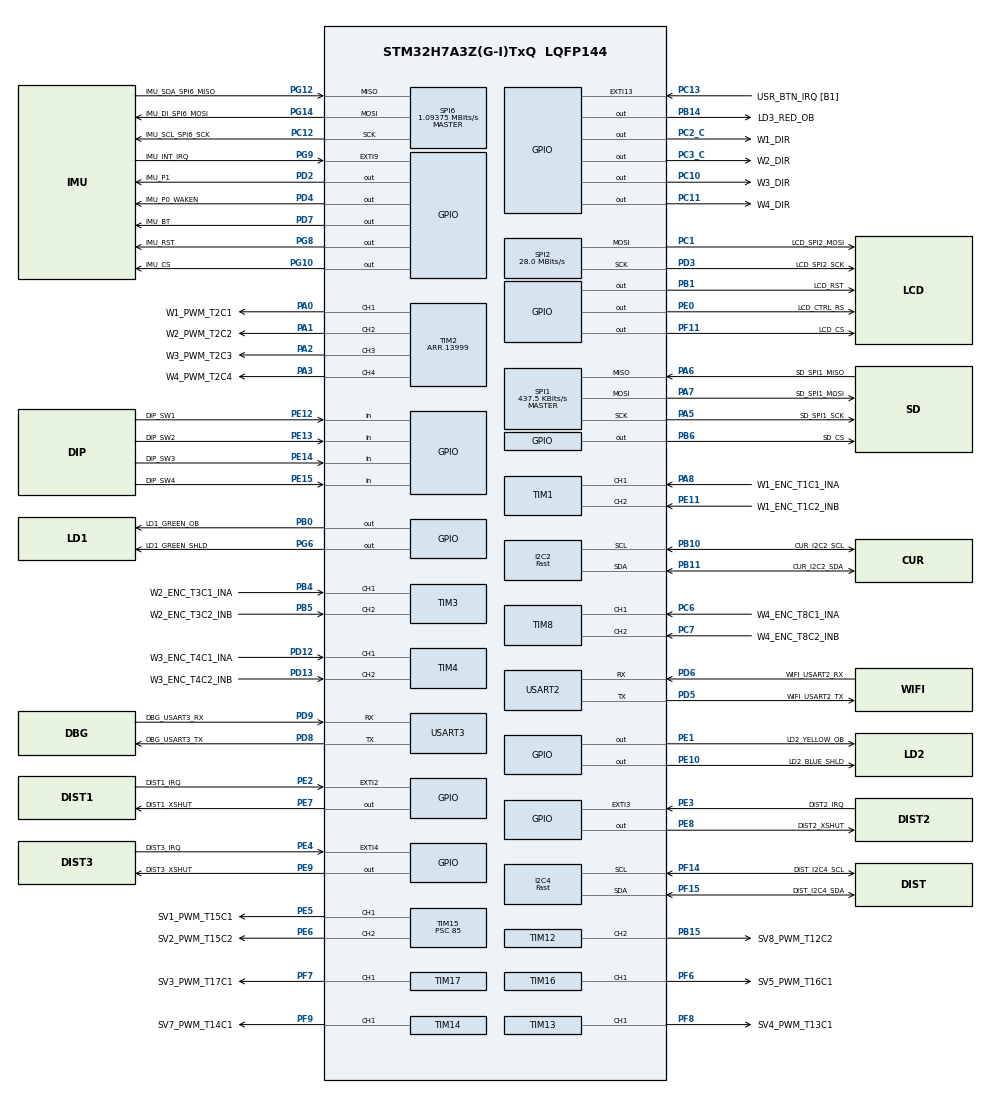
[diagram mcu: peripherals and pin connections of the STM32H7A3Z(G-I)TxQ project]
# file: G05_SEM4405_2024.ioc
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ADC2.Channel-0\#ChannelRegularConversion=ADC_CHANNEL_TEMPSENSOR
ADC2.ContinuousConvMode=ENABLE
ADC2.NbrOfConversionFlag=1
ADC2.OffsetNumber-0\#ChannelRegularConversion=ADC_OFFSET_NONE
ADC2.OffsetSignedSaturation-0\#ChannelRegularConversion=DISABLE
ADC2.Rank-0\#ChannelRegularConversion=1
ADC2.SamplingTime-0\#ChannelRegularConversion=ADC_SAMPLETIME_810CYCLES_5
FREERTOS.BinarySemaphores01=SemaUartTx,Dynamic,NULL
FREERTOS.Events01=eventSysFlags,Dynamic,NULL;eventLcdReady,Dynamic,NULL;eventUartTxReady,Dynamic,NULL;eventUartRxReady,Dynamic,NULL
FREERTOS.Tasks01=debugPrintTask,24,2048,StartDebugPrintTask,Default,&robot,Dynamic,NULL,NULL;adcTask,40,2048,StartAdcTask,Default,&robot,Dynamic,NULL,NULL;curSenTask,40,2048,StartCurSenTask,Default,&robot,Dynamic,NULL,NULL;distSenTask,40,2048,StartDistSenTask,Default,&robot,Dynamic,NULL,NULL;sdCardTask,8,2048,StartSdCardTask,Default,&robot,Dynamic,NULL,NULL;mtrEncoderTask,48,2048,StartMtrEncoderTask,Default,&robot,Dynamic,NULL,NULL;srvPwmUpdateTask,40,2048,StartSrvPwmUpdateTask,Default,&robot,Dynamic,NULL,NULL;cmdRxTask,40,2048,StartCmdRxTask,Default,&robot,Dynamic,NULL,NULL;guiLcdDispTask,24,2048,StartGuiLcdDispTask,Default,&robot,Dynamic,NULL,NULL;imuTask,40,2048,StartImuTask,Default,&robot ,Dynamic,NULL,NULL
FREERTOS.configCHECK_FOR_STACK_OVERFLOW=2
FREERTOS.configMAX_TASK_NAME_LEN=18
FREERTOS.configMINIMAL_STACK_SIZE=1024
FREERTOS.configTOTAL_HEAP_SIZE=204800
FREERTOS.configUSE_MALLOC_FAILED_HOOK=1
FREERTOS.configUSE_NEWLIB_REENTRANT=1
I2C2.I2C_Speed_Mode=I2C_Fast
I2C2.OwnAddress=0x40
I2C2.Timing=0x00D04BFF
I2C4.I2C_Speed_Mode=I2C_Fast
I2C4.OwnAddress=0x29
I2C4.Timing=0x00D04BFF
Mcu.Family=STM32H7
Mcu.Name=STM32H7A3Z(G-I)TxQ
Mcu.Package=LQFP144
NVIC.ADC_IRQn=true\:5\:0\:false\:false\:true\:true\:true\:true\:true
NVIC.EXTI15_10_IRQn=true\:5\:0\:false\:false\:true\:true\:true\:true\:true
NVIC.EXTI2_IRQn=true\:5\:0\:false\:false\:true\:true\:true\:true\:true
NVIC.EXTI3_IRQn=true\:5\:0\:false\:false\:true\:true\:true\:true\:true
NVIC.EXTI4_IRQn=true\:5\:0\:false\:false\:true\:true\:true\:true\:true
NVIC.EXTI9_5_IRQn=true\:5\:0\:false\:false\:true\:true\:true\:true\:true
NVIC.PriorityGroup=NVIC_PRIORITYGROUP_4
NVIC.SPI2_IRQn=true\:5\:0\:false\:false\:true\:true\:true\:true\:true
NVIC.SPI6_IRQn=true\:5\:0\:false\:false\:true\:true\:true\:true\:true
NVIC.TIM7_IRQn=true\:15\:0\:false\:false\:true\:false\:false\:true\:true
NVIC.TimeBase=TIM7_IRQn
NVIC.TimeBaseIP=TIM7
NVIC.USART2_IRQn=true\:5\:0\:false\:false\:true\:true\:true\:true\:true
PA0.GPIO_Label=W1_PWM_T2C1 
PA0.Signal=S_TIM2_CH1_ETR
PA1.GPIO_Label=W2_PWM_T2C2 
PA1.Signal=S_TIM2_CH2
PA13.GPIO_Label=DBG_SWDIO
PA13.Mode=Trace_Asynchronous_SW
PA13.Signal=DEBUG_JTMS-SWDIO
PA14.GPIO_Label=DBG_SWCLK
PA14.Mode=Trace_Asynchronous_SW
PA14.Signal=DEBUG_JTCK-SWCLK
PA2.GPIO_Label=W3_PWM_T2C3
PA2.Signal=S_TIM2_CH3
PA3.GPIO_Label=W4_PWM_T2C4 
PA3.Signal=S_TIM2_CH4
PA5.GPIO_Label=SD_SPI1_SCK
PA5.GPIO_Speed=GPIO_SPEED_FREQ_VERY_HIGH
PA5.Mode=Full_Duplex_Master
PA5.Signal=SPI1_SCK
PA6.GPIO_Label=SD_SPI1_MISO 
PA6.GPIO_PuPd=GPIO_PULLUP
PA6.GPIO_Speed=GPIO_SPEED_FREQ_VERY_HIGH
PA6.Mode=Full_Duplex_Master
PA6.Signal=SPI1_MISO
PA7.GPIO_Label=SD_SPI1_MOSI 
PA7.GPIO_PuPd=GPIO_PULLUP
PA7.GPIO_Speed=GPIO_SPEED_FREQ_VERY_HIGH
PA7.Mode=Full_Duplex_Master
PA7.Signal=SPI1_MOSI
PA8.GPIO_Label=W1_ENC_T1C1_INA
PA8.Signal=S_TIM1_CH1
PB0.GPIO_Label=LD1_GREEN_OB
PB0.Signal=GPIO_Output
PB1.GPIO_Label=LCD_RST
PB1.Signal=GPIO_Output
PB10.GPIO_Label=CUR_I2C2_SCL
PB10.Mode=I2C
PB10.Signal=I2C2_SCL
PB11.GPIO_Label=CUR_I2C2_SDA
PB11.Mode=I2C
PB11.Signal=I2C2_SDA
PB14.GPIO_Label=LD3_RED_OB
PB14.Signal=GPIO_Output
PB15.GPIO_Label=SV8_PWM_T12C2
PB15.Signal=S_TIM12_CH2
PB3.GPIO_Label=DBG_SWO
PB3.Mode=Trace_Asynchronous_SW
PB3.Signal=DEBUG_JTDO-SWO
PB4.GPIO_Label=W2_ENC_T3C1_INA
PB4.Signal=S_TIM3_CH1
PB5.GPIO_Label=W2_ENC_T3C2_INB
PB5.Signal=S_TIM3_CH2
PB6.GPIO_Label=SD_CS
PB6.Signal=GPIO_Output
PC1.GPIO_Label=LCD_SPI2_MOSI
PC1.GPIO_Speed=GPIO_SPEED_FREQ_VERY_HIGH
PC1.Mode=TX_Only_Simplex_Unidirect_Master
PC1.Signal=SPI2_MOSI
PC10.GPIO_Label=W3_DIR
PC10.Signal=GPIO_Output
PC11.GPIO_Label=W4_DIR
PC11.Signal=GPIO_Output
PC12.GPIO_Label=IMU_SCL_SPI6_SCK
PC12.GPIO_Speed=GPIO_SPEED_FREQ_VERY_HIGH
PC12.Mode=Full_Duplex_Master
PC12.Signal=SPI6_SCK
PC13.GPIO_Label=USR_BTN_IRQ [B1] 
PC13.Signal=GPXTI13
PC14-OSC32_IN.GPIO_Label=OSC32_IN
PC14-OSC32_IN.Mode=LSE-External-Oscillator
PC14-OSC32_IN.Signal=RCC_OSC32_IN
PC15-OSC32_OUT.GPIO_Label=OSC32_OUT
PC15-OSC32_OUT.Mode=LSE-External-Oscillator
PC15-OSC32_OUT.Signal=RCC_OSC32_OUT
PC2_C.GPIO_Label=W1_DIR
PC2_C.Signal=GPIO_Output
PC3_C.GPIO_Label=W2_DIR
PC3_C.Signal=GPIO_Output
PC6.GPIO_Label=W4_ENC_T8C1_INA
PC6.Signal=S_TIM8_CH1
PC7.GPIO_Label=W4_ENC_T8C2_INB 
PC7.Signal=S_TIM8_CH2
PD12.GPIO_Label=W3_ENC_T4C1_INA
PD12.Signal=S_TIM4_CH1
PD13.GPIO_Label=W3_ENC_T4C2_INB
PD13.Signal=S_TIM4_CH2
PD2.GPIO_Label=IMU_P1
PD2.Signal=GPIO_Output
PD3.GPIO_Label=LCD_SPI2_SCK
PD3.GPIO_Speed=GPIO_SPEED_FREQ_VERY_HIGH
PD3.Mode=TX_Only_Simplex_Unidirect_Master
PD3.Signal=SPI2_SCK
PD4.GPIO_Label=IMU_P0_WAKEN
PD4.Signal=GPIO_Output
PD5.GPIO_Label=WIFI_USART2_TX
PD5.Mode=Asynchronous
PD5.Signal=USART2_TX
PD6.GPIO_Label=WIFI_USART2_RX
PD6.Mode=Asynchronous
PD6.Signal=USART2_RX
PD7.GPIO_Label=IMU_BT
PD7.Signal=GPIO_Output
PD8.GPIO_Label=DBG_USART3_TX
PD8.Mode=Asynchronous
PD8.Signal=USART3_TX
PD9.GPIO_Label=DBG_USART3_RX
PD9.Mode=Asynchronous
PD9.Signal=USART3_RX
PE0.GPIO_Label=LCD_CTRL_RS
PE0.Signal=GPIO_Output
PE1.GPIO_Label=LD2_YELLOW_OB 
PE1.Signal=GPIO_Output
PE10.GPIO_Label=LD2_BLUE_SHLD
PE10.Signal=GPIO_Output
PE11.GPIO_Label=W1_ENC_T1C2_INB
PE11.Signal=S_TIM1_CH2
PE12.GPIO_Label=DIP_SW1
PE12.Signal=GPIO_Input
PE13.GPIO_Label=DIP_SW2
PE13.Signal=GPIO_Input
PE14.GPIO_Label=DIP_SW3
PE14.Signal=GPIO_Input
PE15.GPIO_Label=DIP_SW4 
PE15.Signal=GPIO_Input
PE2.GPIO_Label=DIST1_IRQ
PE2.Signal=GPXTI2
PE3.GPIO_Label=DIST2_IRQ
PE3.Signal=GPXTI3
PE4.GPIO_Label=DIST3_IRQ
PE4.Signal=GPXTI4
PE5.GPIO_Label=SV1_PWM_T15C1
PE5.Signal=S_TIM15_CH1
PE6.GPIO_Label=SV2_PWM_T15C2
PE6.Signal=S_TIM15_CH2
PE7.GPIO_Label=DIST1_XSHUT
PE7.Signal=GPIO_Output
PE8.GPIO_Label=DIST2_XSHUT
PE8.Signal=GPIO_Output
PE9.GPIO_Label=DIST3_XSHUT
PE9.Signal=GPIO_Output
PF11.GPIO_Label=LCD_CS
PF11.Signal=GPIO_Output
PF14.GPIO_Label=DIST_I2C4_SCL
PF14.Mode=I2C
PF14.Signal=I2C4_SCL
PF15.GPIO_Label=DIST_I2C4_SDA
PF15.Mode=I2C
PF15.Signal=I2C4_SDA
PF6.GPIO_Label=SV5_PWM_T16C1
PF6.Signal=S_TIM16_CH1
PF7.GPIO_Label=SV3_PWM_T17C1 
PF7.Signal=S_TIM17_CH1
PF8.GPIO_Label=SV4_PWM_T13C1
PF8.Signal=S_TIM13_CH1
PF9.GPIO_Label=SV7_PWM_T14C1
PF9.Signal=S_TIM14_CH1
PG10.GPIO_Label=IMU_CS
PG10.Signal=GPIO_Output
PG12.GPIO_Label=IMU_SDA_SPI6_MISO
PG12.GPIO_Speed=GPIO_SPEED_FREQ_VERY_HIGH
PG12.Mode=Full_Duplex_Master
PG12.Signal=SPI6_MISO
PG14.GPIO_Label=IMU_DI_SPI6_MOSI 
PG14.GPIO_Speed=GPIO_SPEED_FREQ_VERY_HIGH
PG14.Mode=Full_Duplex_Master
PG14.Signal=SPI6_MOSI
PG6.GPIO_Label=LD1_GREEN_SHLD
PG6.Signal=GPIO_Output
PG8.GPIO_Label=IMU_RST
PG8.Signal=GPIO_Output
PG9.GPIO_Label=IMU_INT_IRQ
PG9.GPIO_ModeDefaultEXTI=GPIO_MODE_IT_FALLING
PG9.GPIO_PuPd=GPIO_PULLUP
PG9.Signal=GPXTI9
PH0-OSC_IN.GPIO_Label=PH0-MCU
PH0-OSC_IN.Mode=HSE-External-Clock-Source
PH0-OSC_IN.Signal=RCC_OSC_IN
ProjectManager.HeapSize=0x200
ProjectManager.StackSize=0x400
ProjectManager.TargetToolchain=STM32CubeIDE
RCC.ADCFreq_Value=32000000
RCC.APB1Freq_Value=140000000
RCC.APB2Freq_Value=140000000
RCC.APB3Freq_Value=140000000
RCC.APB4Freq_Value=140000000
RCC.CDPPRE=RCC_APB3_DIV2
RCC.CDPPRE1=RCC_APB1_DIV2
RCC.CDPPRE2=RCC_APB2_DIV2
RCC.CortexFreq_Value=280000000
RCC.DIVM1=1
RCC.DIVM2=1
RCC.DIVM3=1
RCC.DIVN1=70
RCC.DIVN2=16
RCC.DIVN3=24
RCC.DIVP2=4
RCC.DIVQ1=5
RCC.HCLKFreq_Value=280000000
RCC.HSE_VALUE=8000000
RCC.PLLFRACN=0
RCC.PLLSourceVirtual=RCC_PLLSOURCE_HSE
RCC.PWR_Regulator_Voltage_Scale=PWR_REGULATOR_VOLTAGE_SCALE0
RCC.SRDPPRE=RCC_APB4_DIV2
RCC.SYSCLKFreq_VALUE=280000000
RCC.SYSCLKSource=RCC_SYSCLKSOURCE_PLLCLK
RCC.SupplySource=PWR_DIRECT_SMPS_SUPPLY
RCC.USBCLockSelection=RCC_USBCLKSOURCE_HSI48
RCC.USBFreq_Value=48000000
SH.S_TIM12_CH2.0=TIM12_CH2,PWM Generation2 CH2
SH.S_TIM13_CH1.0=TIM13_CH1,PWM Generation1 CH1
SH.S_TIM14_CH1.0=TIM14_CH1,PWM Generation1 CH1
SH.S_TIM15_CH1.0=TIM15_CH1,PWM Generation1 CH1
SH.S_TIM15_CH2.0=TIM15_CH2,PWM Generation2 CH2
SH.S_TIM16_CH1.0=TIM16_CH1,PWM Generation1 CH1
SH.S_TIM17_CH1.0=TIM17_CH1,PWM Generation1 CH1
SH.S_TIM1_CH1.0=TIM1_CH1,Encoder_Interface
SH.S_TIM1_CH2.0=TIM1_CH2,Encoder_Interface
SH.S_TIM2_CH1_ETR.0=TIM2_CH1,PWM Generation1 CH1
SH.S_TIM2_CH2.0=TIM2_CH2,PWM Generation2 CH2
SH.S_TIM2_CH3.0=TIM2_CH3,PWM Generation3 CH3
SH.S_TIM2_CH4.0=TIM2_CH4,PWM Generation4 CH4
SH.S_TIM3_CH1.0=TIM3_CH1,Encoder_Interface
SH.S_TIM3_CH2.0=TIM3_CH2,Encoder_Interface
SH.S_TIM4_CH1.0=TIM4_CH1,Encoder_Interface
SH.S_TIM4_CH2.0=TIM4_CH2,Encoder_Interface
SH.S_TIM8_CH1.0=TIM8_CH1,Encoder_Interface
SH.S_TIM8_CH2.0=TIM8_CH2,Encoder_Interface
SPI1.BaudRatePrescaler=SPI_BAUDRATEPRESCALER_256
SPI1.CalculateBaudRate=437.5 KBits/s
SPI1.DataSize=SPI_DATASIZE_8BIT
SPI1.Direction=SPI_DIRECTION_2LINES
SPI1.Mode=SPI_MODE_MASTER
SPI1.VirtualType=VM_MASTER
SPI2.BaudRatePrescaler=SPI_BAUDRATEPRESCALER_4
SPI2.CalculateBaudRate=28.0 MBits/s
SPI2.DataSize=SPI_DATASIZE_8BIT
SPI2.Direction=SPI_DIRECTION_2LINES_TXONLY
SPI2.Mode=SPI_MODE_MASTER
SPI2.VirtualType=VM_MASTER
SPI6.BaudRatePrescaler=SPI_BAUDRATEPRESCALER_128
SPI6.CLKPhase=SPI_PHASE_2EDGE
SPI6.CLKPolarity=SPI_POLARITY_HIGH
SPI6.CalculateBaudRate=1.09375 MBits/s
SPI6.DataSize=SPI_DATASIZE_8BIT
SPI6.Direction=SPI_DIRECTION_2LINES
SPI6.Mode=SPI_MODE_MASTER
SPI6.VirtualType=VM_MASTER
TIM1.EncoderMode=TIM_ENCODERMODE_TI12
TIM1.IC1Filter=5
TIM1.IC2Filter=5
TIM12.AutoReloadPreload=TIM_AUTORELOAD_PRELOAD_ENABLE
TIM12.Channel-PWM\ Generation2\ CH2=TIM_CHANNEL_2
TIM12.Period=65115
TIM12.Prescaler=85
TIM12.Pulse-PWM\ Generation2\ CH2=4883
TIM13.AutoReloadPreload=TIM_AUTORELOAD_PRELOAD_ENABLE
TIM13.Channel=TIM_CHANNEL_1
TIM13.Period=65115
TIM13.Prescaler=85
TIM13.Pulse=4883
TIM14.AutoReloadPreload=TIM_AUTORELOAD_PRELOAD_ENABLE
TIM14.Channel=TIM_CHANNEL_1
TIM14.Period=65115
TIM14.Prescaler=85
TIM14.Pulse=4883
TIM15.AutoReloadPreload=TIM_AUTORELOAD_PRELOAD_ENABLE
TIM15.Channel-PWM\ Generation1\ CH1=TIM_CHANNEL_1
TIM15.Channel-PWM\ Generation2\ CH2=TIM_CHANNEL_2
TIM15.Period=65115
TIM15.Prescaler=85
TIM15.Pulse-PWM\ Generation1\ CH1=4883
TIM15.Pulse-PWM\ Generation2\ CH2=4883
TIM16.AutoReloadPreload=TIM_AUTORELOAD_PRELOAD_ENABLE
TIM16.Channel=TIM_CHANNEL_1
TIM16.Period=65115
TIM16.Prescaler=85
TIM16.Pulse=4883
TIM17.AutoReloadPreload=TIM_AUTORELOAD_PRELOAD_ENABLE
TIM17.Channel=TIM_CHANNEL_1
TIM17.Period=65115
TIM17.Prescaler=85
TIM17.Pulse=4883
TIM2.AutoReloadPreload=TIM_AUTORELOAD_PRELOAD_ENABLE
TIM2.Channel-PWM\ Generation1\ CH1=TIM_CHANNEL_1
TIM2.Channel-PWM\ Generation2\ CH2=TIM_CHANNEL_2
TIM2.Channel-PWM\ Generation3\ CH3=TIM_CHANNEL_3
TIM2.Channel-PWM\ Generation4\ CH4=TIM_CHANNEL_4
TIM2.Period=13999
TIM3.EncoderMode=TIM_ENCODERMODE_TI12
TIM3.IC1Filter=5
TIM3.IC2Filter=5
TIM4.EncoderMode=TIM_ENCODERMODE_TI12
TIM4.IC1Filter=5
TIM4.IC2Filter=5
TIM5.Prescaler=279
TIM8.EncoderMode=TIM_ENCODERMODE_TI12
TIM8.IC1Filter=5
TIM8.IC2Filter=5
USART2.VirtualMode-Asynchronous=VM_ASYNC
USART3.VirtualMode-Asynchronous=VM_ASYNC
VP_ADC2_TempSens_Input.Mode=IN-TempSens
VP_CRC_VS_CRC.Mode=CRC_Activate
VP_FATFS_VS_Generic.Mode=User_defined
VP_FREERTOS_VS_CMSIS_V2.Mode=CMSIS_V2
VP_SYS_VS_tim7.Mode=TIM7
VP_TIM13_VS_ClockSourceINT.Mode=Enable_Timer
VP_TIM14_VS_ClockSourceINT.Mode=Enable_Timer
VP_TIM16_VS_ClockSourceINT.Mode=Enable_Timer
VP_TIM17_VS_ClockSourceINT.Mode=Enable_Timer
VP_TIM2_VS_ClockSourceINT.Mode=Internal
VP_TIM5_VS_ClockSourceINT.Mode=Internal
board=NUCLEO-H7A3ZI-Q

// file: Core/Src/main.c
/* USER CODE BEGIN Header */
/**
  ******************************************************************************
  * @file           : main.c
  * @brief          : Main program body
  ******************************************************************************
  * @attention
  *
  * Copyright (c) 2024 STMicroelectronics.
  * All rights reserved.
  *
  * This software is licensed under terms that can be found in the LICENSE file
  * in the root directory of this software component.
  * If no LICENSE file comes with this software, it is provided AS-IS.
  *
  ******************************************************************************
  */
/* USER CODE END Header */
#include "main.h"
#include "cmsis_os.h"
#include "adc.h"
#include "crc.h"
#include "fatfs.h"
#include "i2c.h"
#include "spi.h"
#include "tim.h"
#include "usart.h"
#include "gpio.h"

/* USER CODE BEGIN Includes */
#include "command.h"
#include "actuator.h"
#include <stdio.h>
/* USER CODE END Includes */

/* USER CODE BEGIN PV */
ROBOT robot = {0};
CMD_HANDLE g_CmdHandle;
/* USER CODE END PV */

void SystemClock_Config(void);
void MX_FREERTOS_Init(void);

int main(void)
{

  /* MCU Configuration--------------------------------------------------------*/

  /* Reset of all peripherals, Initializes the Flash interface and the Systick. */
  HAL_Init();

  /* Configure the system clock */
  SystemClock_Config();

  /* Initialize all configured peripherals */
  MX_GPIO_Init();
  MX_USART3_UART_Init();
  MX_SPI1_Init();
  MX_USART2_UART_Init();
  MX_I2C2_Init();
  MX_I2C4_Init();
  MX_SPI2_Init();
  MX_FATFS_Init();
  MX_ADC2_Init();
  MX_CRC_Init();
  MX_SPI6_Init();
  MX_TIM1_Init();
  MX_TIM2_Init();
  MX_TIM3_Init();
  MX_TIM4_Init();
  MX_TIM5_Init();
  MX_TIM8_Init();
  MX_TIM12_Init();
  MX_TIM13_Init();
  MX_TIM14_Init();
  MX_TIM15_Init();
  MX_TIM16_Init();
  MX_TIM17_Init();
  /* USER CODE BEGIN 2 */
  // start encoder reading, motor 1 and motor 2
  HAL_TIM_Encoder_Start(&E1_TIM, TIM_CHANNEL_ALL);
  HAL_TIM_Encoder_Start(&E2_TIM, TIM_CHANNEL_ALL);
  // HAL_TIM_Encoder_Start(&E3_TIM, TIM_CHANNEL_ALL);
  // HAL_TIM_Encoder_Start(&E4_TIM, TIM_CHANNEL_ALL);

  // enable/start motor PWM outputs, motor 1 and 2 -> timer 15-1, 15-2
  HAL_TIM_PWM_Start(&M1_TIM,M1_CHANNEL);
  HAL_TIM_PWM_Start(&M2_TIM,M2_CHANNEL);
  // enable/start servo PWM outputs, servo 1,2,3,4,5,6,7,8
  HAL_TIM_PWM_Start(&S1_TIM,S1_CHANNEL); //servo 1, index[0] base link 1
  HAL_TIM_PWM_Start(&S2_TIM,S2_CHANNEL); //servo 2, index[1] link 2
  HAL_TIM_PWM_Start(&S3_TIM,S3_CHANNEL); //servo 3, index[2] rotate
  HAL_TIM_PWM_Start(&S4_TIM,S4_CHANNEL); //servo 4, index[3] gripper
  HAL_TIM_PWM_Start(&S5_TIM,S5_CHANNEL); //servo 5, index[4] not used
  // HAL_TIM_PWM_Start(&S6_TIM,S6_CHANNEL); //servo 6, index[5] not implemented
  HAL_TIM_PWM_Start(&S7_TIM,S7_CHANNEL); //servo 7, index[6] Camera pan
  HAL_TIM_PWM_Start(&S8_TIM,S8_CHANNEL); //servo 8, index[7] camera tilt
  // Dip switch value
  robot.dipSwValue = 0;
  if( HAL_GPIO_ReadPin(GPIOE, DIP_SW1_Pin) == GPIO_PIN_SET ) robot.dipSwValue = 1;
  if( HAL_GPIO_ReadPin(GPIOE, DIP_SW2_Pin) == GPIO_PIN_SET ) robot.dipSwValue += 2;
  if( HAL_GPIO_ReadPin(GPIOE, DIP_SW3_Pin) == GPIO_PIN_SET ) robot.dipSwValue += 4;
  if( HAL_GPIO_ReadPin(GPIOE, DIP_SW4_Pin) == GPIO_PIN_SET ) robot.dipSwValue += 8;
  printf("\r\nDIP_SW = %d\r\n", robot.dipSwValue);
  // WiFi Serial to net command initialization
  // initial here as more than one tasks need to access Command
  CommandInit( &g_CmdHandle, &huart2 );
  printf("\r\nRobot Command Interpreter is initialized.\r\n");
  // set PWM values in CommandInit() for robot estimated zero positions
  // set joint offset, direction, plus and minus limits
  robot.dataSrvPos.jointAngleOffset[0] = 9000; // 9000 = 90.00 degree, joint 1, lower arm
  robot.dataSrvPos.jointAngleDir[0] = -1; // +1 or -1
  robot.dataSrvPos.jointAnglePlusLimit[0] = 9000;
  robot.dataSrvPos.jointAngleMinusLimit[0] = -5000;
  robot.dataSrvPos.jointAngleOffset[1] = 17000; // joint 2, upper arm
  robot.dataSrvPos.jointAngleDir[1] = -1;
  robot.dataSrvPos.jointAnglePlusLimit[1] = 13500;
  robot.dataSrvPos.jointAngleMinusLimit[1] = -500;
  robot.dataSrvPos.jointAngleOffset[2] = 11000; // rotate gripper
  robot.dataSrvPos.jointAngleDir[2] = 1;
  robot.dataSrvPos.jointAnglePlusLimit[2] = 6000;
  robot.dataSrvPos.jointAngleMinusLimit[2] = -6000;
  robot.dataSrvPos.jointAngleOffset[3] = 6000; //gripper
  robot.dataSrvPos.jointAngleDir[3] = -1;
  robot.dataSrvPos.jointAnglePlusLimit[3] = 4000;
  robot.dataSrvPos.jointAngleMinusLimit[3] = 0;
  robot.dataSrvPos.jointAngleOffset[4] = 0;
  robot.dataSrvPos.jointAngleDir[4] = 1;
  robot.dataSrvPos.jointAnglePlusLimit[4] = 0;
  robot.dataSrvPos.jointAngleMinusLimit[4] = 0;
  robot.dataSrvPos.jointAngleOffset[5] = 0;
  robot.dataSrvPos.jointAngleDir[5] = 1;
  robot.dataSrvPos.jointAnglePlusLimit[5] = 0;
  robot.dataSrvPos.jointAngleMinusLimit[5] = 0;
  robot.dataSrvPos.jointAngleOffset[6] = 9000; // pan
  robot.dataSrvPos.jointAngleDir[6] = 1;
  robot.dataSrvPos.jointAnglePlusLimit[6] = 6000;
  robot.dataSrvPos.jointAngleMinusLimit[6] = -6000;
  robot.dataSrvPos.jointAngleOffset[7] = 9000; // title
  robot.dataSrvPos.jointAngleDir[7] = 1;
  robot.dataSrvPos.jointAnglePlusLimit[7] = 6000;
  robot.dataSrvPos.jointAngleMinusLimit[7] = -6000;
  // For each joint, set zero joint position after offset adjustment
  for (int i = 0; i < 8; i++)
  {
  robot.dataSrvPos.jointAngle[i] = 0;
  g_CmdHandle.TargetPwm[i].Value = ServoJointAngleToPWM( i+1, robot.dataSrvPos.jointAngle[i] );
  robot.dataSrvPwm.currentPwm[i] = g_CmdHandle.TargetPwm[i].Value;
  ServoSetDuty( i+1, robot.dataSrvPwm.currentPwm[i]);
  }
  /* USER CODE END 2 */

  /* Init scheduler */
  osKernelInitialize();

  /* Call init function for freertos objects (in freertos.c) */
  MX_FREERTOS_Init();

  /* Start scheduler */
  osKernelStart();

  /* We should never get here as control is now taken by the scheduler */
  /* Infinite loop */
  while (1)
  {

  }
}

void SystemClock_Config(void)
{
  RCC_OscInitTypeDef RCC_OscInitStruct = {0};
  RCC_ClkInitTypeDef RCC_ClkInitStruct = {0};

  /*AXI clock gating */
  RCC->CKGAENR = 0xFFFFFFFF;

  /** Supply configuration update enable
  */
  HAL_PWREx_ConfigSupply(PWR_DIRECT_SMPS_SUPPLY);

  /** Configure the main internal regulator output voltage
  */
  __HAL_PWR_VOLTAGESCALING_CONFIG(PWR_REGULATOR_VOLTAGE_SCALE0);

  while(!__HAL_PWR_GET_FLAG(PWR_FLAG_VOSRDY)) {}

  /** Initializes the RCC Oscillators according to the specified parameters
  * in the RCC_OscInitTypeDef structure.
  */
  RCC_OscInitStruct.OscillatorType = RCC_OSCILLATORTYPE_HSE;
  RCC_OscInitStruct.HSEState = RCC_HSE_BYPASS;
  RCC_OscInitStruct.PLL.PLLState = RCC_PLL_ON;
  RCC_OscInitStruct.PLL.PLLSource = RCC_PLLSOURCE_HSE;
  RCC_OscInitStruct.PLL.PLLM = 1;
  RCC_OscInitStruct.PLL.PLLN = 70;
  RCC_OscInitStruct.PLL.PLLP = 2;
  RCC_OscInitStruct.PLL.PLLQ = 5;
  RCC_OscInitStruct.PLL.PLLR = 2;
  RCC_OscInitStruct.PLL.PLLRGE = RCC_PLL1VCIRANGE_3;
  RCC_OscInitStruct.PLL.PLLVCOSEL = RCC_PLL1VCOWIDE;
  RCC_OscInitStruct.PLL.PLLFRACN = 0;
  if (HAL_RCC_OscConfig(&RCC_OscInitStruct) != HAL_OK)
  {
    Error_Handler();
  }

  /** Initializes the CPU, AHB and APB buses clocks
  */
  RCC_ClkInitStruct.ClockType = RCC_CLOCKTYPE_HCLK|RCC_CLOCKTYPE_SYSCLK
                              |RCC_CLOCKTYPE_PCLK1|RCC_CLOCKTYPE_PCLK2
                              |RCC_CLOCKTYPE_D3PCLK1|RCC_CLOCKTYPE_D1PCLK1;
  RCC_ClkInitStruct.SYSCLKSource = RCC_SYSCLKSOURCE_PLLCLK;
  RCC_ClkInitStruct.SYSCLKDivider = RCC_SYSCLK_DIV1;
  RCC_ClkInitStruct.AHBCLKDivider = RCC_HCLK_DIV1;
  RCC_ClkInitStruct.APB3CLKDivider = RCC_APB3_DIV2;
  RCC_ClkInitStruct.APB1CLKDivider = RCC_APB1_DIV2;
  RCC_ClkInitStruct.APB2CLKDivider = RCC_APB2_DIV2;
  RCC_ClkInitStruct.APB4CLKDivider = RCC_APB4_DIV2;

  if (HAL_RCC_ClockConfig(&RCC_ClkInitStruct, FLASH_LATENCY_6) != HAL_OK)
  {
    Error_Handler();
  }
}

void HAL_TIM_PeriodElapsedCallback(TIM_HandleTypeDef *htim)
{
  if (htim->Instance == TIM7) {
    HAL_IncTick();
  }
}

void Error_Handler(void)
{
  __disable_irq();
  while (1)
  {
  }
}

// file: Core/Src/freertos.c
/* USER CODE BEGIN Header */
/**
  ******************************************************************************
  * File Name          : freertos.c
  * Description        : Code for freertos applications
  ******************************************************************************
  * @attention
  *
  * Copyright (c) 2024 STMicroelectronics.
  * All rights reserved.
  *
  * This software is licensed under terms that can be found in the LICENSE file
  * in the root directory of this software component.
  * If no LICENSE file comes with this software, it is provided AS-IS.
  *
  ******************************************************************************
  */
/* USER CODE END Header */

#include "FreeRTOS.h"
#include "task.h"
#include "main.h"
#include "cmsis_os.h"

/* USER CODE BEGIN Includes */
#include <stdio.h>
#include <stdlib.h>
#include <string.h>
#include "adc.h"
#include "crc.h"
#include "fatfs.h"
#include "sd_card.h"
#include "i2c.h"
#include "spi.h"
#include "tim.h"
#include "usart.h"
#include "gpio.h"
#include "ina219.h"
#include "VL53L0x_DistanceSensor.h"
#include "LCD_Driver.h"
#include "GUI.h"
#include "BNO085_spi.h"
#include "command.h"
#include "actuator.h"
/* USER CODE END Includes */

/* USER CODE BEGIN PD */
#define DEBUG_PRINT_DELAY (3000) // Task 1
#define ADC_TASK_DELAY (2000) // Task 2
#define CURRENT_SENSE_DELAY (2000) // Task 3
#define DISTANCE_SENSE_DELAY (1000) // Task 4
#define SD_CARD_TASK_DELAY (2000) // Task 5
#define MTR_SAMPLING_TIME (5) // Task 6 (5) 200 Hz
#define SRV_PWM_UPDATE_TIME (20) // Task 7 (20) 50 Hz
// #define COMMAND_RX_DELAY (20) // Task 8
#define GUI_LCD_DISP_DELAY (3000) // Task 9
#define IMU_TASK_DELAY (1000) // Task 10

#define EVT_SYS_FLAG_GUI_READY (uint32_t)(0x00000001)
#define EVT_SYS_FLAG_DIS_READY (uint32_t)(0x00000002)
#define EVT_SYS_FLAG_ADC_READY (uint32_t)(0x00000004)
#define EVT_SYS_FLAG_CUR_READY (uint32_t)(0x00000008)
#define EVT_SYS_FLAG_SDC_READY (uint32_t)(0x00000010)
#define EVT_SYS_FLAG_IMU_READY (uint32_t)(0x00000020)
#define EVT_SYS_FLAG_ALL_READY (uint32_t)(0x00000040)

// temperature sensor calibration value addresses
#define TS_CAL1 ((uint16_t*)((uint32_t)0x08FFF814))
#define TS_CAL2 ((uint16_t*)((uint32_t)0x08FFF818))

/* USER CODE END PD */

/* USER CODE BEGIN Variables */
// Global structure
extern ROBOT robot;
extern CMD_HANDLE g_CmdHandle;
/* USER CODE END Variables */
/* Definitions for debugPrintTask */
osThreadId_t debugPrintTaskHandle;
const osThreadAttr_t debugPrintTask_attributes = {
  .name = "debugPrintTask",
  .stack_size = 2048 * 4,
  .priority = (osPriority_t) osPriorityNormal,
};
/* Definitions for adcTask */
osThreadId_t adcTaskHandle;
const osThreadAttr_t adcTask_attributes = {
  .name = "adcTask",
  .stack_size = 2048 * 4,
  .priority = (osPriority_t) osPriorityHigh,
};
/* Definitions for curSenTask */
osThreadId_t curSenTaskHandle;
const osThreadAttr_t curSenTask_attributes = {
  .name = "curSenTask",
  .stack_size = 2048 * 4,
  .priority = (osPriority_t) osPriorityHigh,
};
/* Definitions for distSenTask */
osThreadId_t distSenTaskHandle;
const osThreadAttr_t distSenTask_attributes = {
  .name = "distSenTask",
  .stack_size = 2048 * 4,
  .priority = (osPriority_t) osPriorityHigh,
};
/* Definitions for sdCardTask */
osThreadId_t sdCardTaskHandle;
const osThreadAttr_t sdCardTask_attributes = {
  .name = "sdCardTask",
  .stack_size = 2048 * 4,
  .priority = (osPriority_t) osPriorityLow,
};
/* Definitions for mtrEncoderTask */
osThreadId_t mtrEncoderTaskHandle;
const osThreadAttr_t mtrEncoderTask_attributes = {
  .name = "mtrEncoderTask",
  .stack_size = 2048 * 4,
  .priority = (osPriority_t) osPriorityRealtime,
};
/* Definitions for srvPwmUpdateTask */
osThreadId_t srvPwmUpdateTaskHandle;
const osThreadAttr_t srvPwmUpdateTask_attributes = {
  .name = "srvPwmUpdateTask",
  .stack_size = 2048 * 4,
  .priority = (osPriority_t) osPriorityHigh,
};
/* Definitions for cmdRxTask */
osThreadId_t cmdRxTaskHandle;
const osThreadAttr_t cmdRxTask_attributes = {
  .name = "cmdRxTask",
  .stack_size = 2048 * 4,
  .priority = (osPriority_t) osPriorityHigh,
};
/* Definitions for guiLcdDispTask */
osThreadId_t guiLcdDispTaskHandle;
const osThreadAttr_t guiLcdDispTask_attributes = {
  .name = "guiLcdDispTask",
  .stack_size = 2048 * 4,
  .priority = (osPriority_t) osPriorityNormal,
};
/* Definitions for imuTask */
osThreadId_t imuTaskHandle;
const osThreadAttr_t imuTask_attributes = {
  .name = "imuTask",
  .stack_size = 2048 * 4,
  .priority = (osPriority_t) osPriorityHigh,
};
/* Definitions for SemaUartTx */
osSemaphoreId_t SemaUartTxHandle;
const osSemaphoreAttr_t SemaUartTx_attributes = {
  .name = "SemaUartTx"
};
/* Definitions for eventSysFlags */
osEventFlagsId_t eventSysFlagsHandle;
const osEventFlagsAttr_t eventSysFlags_attributes = {
  .name = "eventSysFlags"
};
/* Definitions for eventLcdReady */
osEventFlagsId_t eventLcdReadyHandle;
const osEventFlagsAttr_t eventLcdReady_attributes = {
  .name = "eventLcdReady"
};
/* Definitions for eventUartTxReady */
osEventFlagsId_t eventUartTxReadyHandle;
const osEventFlagsAttr_t eventUartTxReady_attributes = {
  .name = "eventUartTxReady"
};
/* Definitions for eventUartRxReady */
osEventFlagsId_t eventUartRxReadyHandle;
const osEventFlagsAttr_t eventUartRxReady_attributes = {
  .name = "eventUartRxReady"
};

/* USER CODE BEGIN FunctionPrototypes */
static void _LcdInit( void );
/* USER CODE END FunctionPrototypes */

void StartDebugPrintTask(void *argument);
void StartAdcTask(void *argument);
void StartCurSenTask(void *argument);
void StartDistSenTask(void *argument);
void StartSdCardTask(void *argument);
void StartMtrEncoderTask(void *argument);
void StartSrvPwmUpdateTask(void *argument);
void StartCmdRxTask(void *argument);
void StartGuiLcdDispTask(void *argument);
void StartImuTask(void *argument);

void MX_FREERTOS_Init(void); /* (MISRA C 2004 rule 8.1) */

/* Hook prototypes */
void vApplicationStackOverflowHook(xTaskHandle xTask, signed char *pcTaskName);
void vApplicationMallocFailedHook(void);

/* USER CODE BEGIN 4 */
void vApplicationStackOverflowHook(xTaskHandle xTask, signed char *pcTaskName)
{
   /* Run time stack overflow checking is performed if
   configCHECK_FOR_STACK_OVERFLOW is defined to 1 or 2. This hook function is
   called if a stack overflow is detected. */
	printf("FreeRTOS: %s Out of stack\r\n", pcTaskName );
	printf("FreeRTOS: %s Out of stack\r\n", pcTaskName );
	while(1){};

}
/* USER CODE END 4 */

/* USER CODE BEGIN 5 */
void vApplicationMallocFailedHook(void)
{
   /* vApplicationMallocFailedHook() will only be called if
   configUSE_MALLOC_FAILED_HOOK is set to 1 in FreeRTOSConfig.h. It is a hook
   function that will get called if a call to pvPortMalloc() fails.
   pvPortMalloc() is called internally by the kernel whenever a task, queue,
   timer or semaphore is created. It is also called by various parts of the
   demo application. If heap_1.c or heap_2.c are used, then the size of the
   heap available to pvPortMalloc() is defined by configTOTAL_HEAP_SIZE in
   FreeRTOSConfig.h, and the xPortGetFreeHeapSize() API function can be used
   to query the size of free heap space that remains (although it does not
   provide information on how the remaining heap might be fragmented). */
	printf("FreeRTOS: Out of heap\r\n");
	printf("FreeRTOS: Out of heap\r\n");
	while(1){};

}
/* USER CODE END 5 */

void MX_FREERTOS_Init(void) {

  /* Create the semaphores(s) */
  /* creation of SemaUartTx */
  SemaUartTxHandle = osSemaphoreNew(1, 0, &SemaUartTx_attributes);

  /* USER CODE BEGIN RTOS_SEMAPHORES */
  // Semaphore is initialized with zero count, osSemaphoreRelease is to get one count,
  // i.e., ready for osSemaphoreAcquire
  osSemaphoreRelease( SemaUartTxHandle );
  /* add semaphores, ... */
  /* USER CODE END RTOS_SEMAPHORES */

  /* Create the thread(s) */
  /* creation of debugPrintTask */
  debugPrintTaskHandle = osThreadNew(StartDebugPrintTask, (void*) &robot, &debugPrintTask_attributes);

  /* creation of adcTask */
  adcTaskHandle = osThreadNew(StartAdcTask, (void*) &robot, &adcTask_attributes);

  /* creation of curSenTask */
  curSenTaskHandle = osThreadNew(StartCurSenTask, (void*) &robot, &curSenTask_attributes);

  /* creation of distSenTask */
  distSenTaskHandle = osThreadNew(StartDistSenTask, (void*) &robot, &distSenTask_attributes);

  /* creation of sdCardTask */
  sdCardTaskHandle = osThreadNew(StartSdCardTask, (void*) &robot, &sdCardTask_attributes);

  /* creation of mtrEncoderTask */
  mtrEncoderTaskHandle = osThreadNew(StartMtrEncoderTask, (void*) &robot, &mtrEncoderTask_attributes);

  /* creation of srvPwmUpdateTask */
  srvPwmUpdateTaskHandle = osThreadNew(StartSrvPwmUpdateTask, (void*) &robot, &srvPwmUpdateTask_attributes);

  /* creation of cmdRxTask */
  cmdRxTaskHandle = osThreadNew(StartCmdRxTask, (void*) &robot, &cmdRxTask_attributes);

  /* creation of guiLcdDispTask */
  guiLcdDispTaskHandle = osThreadNew(StartGuiLcdDispTask, (void*) &robot, &guiLcdDispTask_attributes);

  /* creation of imuTask */
  imuTaskHandle = osThreadNew(StartImuTask, (void*) &robot, &imuTask_attributes);

  /* Create the event(s) */
  /* creation of eventSysFlags */
  eventSysFlagsHandle = osEventFlagsNew(&eventSysFlags_attributes);

  /* creation of eventLcdReady */
  eventLcdReadyHandle = osEventFlagsNew(&eventLcdReady_attributes);

  /* creation of eventUartTxReady */
  eventUartTxReadyHandle = osEventFlagsNew(&eventUartTxReady_attributes);

  /* creation of eventUartRxReady */
  eventUartRxReadyHandle = osEventFlagsNew(&eventUartRxReady_attributes);

}

void StartDebugPrintTask(void *argument)
{
  /* USER CODE BEGIN StartDebugPrintTask */
  // Task 1
  // Debug Print Task
  ROBOT * rcvData = (ROBOT *) argument;
  char str[128];
  float temperature = 0.0;
  /* Wait for all devices ready */
  osEventFlagsWait( eventSysFlagsHandle, ( EVT_SYS_FLAG_ALL_READY ),
  (osFlagsNoClear | osFlagsWaitAll), osWaitForever );

  /* Infinite loop */
  for(;;)
  {
	  // ADC2 measurement
	  temperature = 100.0 * ((float)rcvData->mcuTempU32 - (float)(*TS_CAL1)) /
	  (float)((*TS_CAL2 - *TS_CAL1)) + 30.0;
	  printf("T_CAL_1_2 = %d %d, Temp = %5.2f (C) \r\n", *TS_CAL1, *TS_CAL2, temperature);
	  // current sensing
	  printf("ShtV = %ld (uV)\r\n", rcvData->dataINA219.shunt_voltage);
	  printf("BusV = %ld (mV)\r\n", rcvData->dataINA219.bus_voltage);
	  // printf("Cur = %ld (0.1 mA) ", rcvData->dataINA219.current);
	  printf("Cur = %7.2f (mA)\r\n", ( (float)(rcvData->dataINA219.current) / 10.0) );
	  printf("Pwr = %ld (mW) \r\n", rcvData->dataINA219.power);

	  for(int i = 0; i < 3; i++)
	  {
		  printf("i = %d, TS= %ld, RS = %d, R_mm = %d \r\n", i+1,
		  rcvData->dataVL53L0X.TimeStamp[i],
		  rcvData->dataVL53L0X.RangeStatus[i],
		  rcvData->dataVL53L0X.RangeMilliMeter[i]);
	  }
	  // motor encoder
	  printf("Mtr 1 encoder = %d \r\n", rcvData->dataEncoder.mtrCnt16AL[0]);
	  printf("Mtr 1 prev cnt = %5d %5d %5d %5d \r\n", rcvData->dataEncoder.mtrCnt16AL[1],
	  rcvData->dataEncoder.mtrCnt16AL[2],
	  rcvData->dataEncoder.mtrCnt16AL[3],
	  rcvData->dataEncoder.mtrCnt16AL[4]);
	  printf("Mtr 2 encoder = %d \r\n", rcvData->dataEncoder.mtrCnt16BR[0]);
	  printf("Mtr 2 prev cnt = %5d %5d %5d %5d \r\n", rcvData->dataEncoder.mtrCnt16BR[1],
	  rcvData->dataEncoder.mtrCnt16BR[2],
	  rcvData->dataEncoder.mtrCnt16BR[3],
	  rcvData->dataEncoder.mtrCnt16BR[4]);
	  printf("Encoder vel 1 = %ld \r\n", rcvData->dataEncoder.mtrVel32AL[0]);
	  printf("Encoder vel 2 = %ld \r\n", rcvData->dataEncoder.mtrVel32BR[0]);
	  printf("S1, L Arm = %ld (x100 deg)\r\n", rcvData->dataSrvPos.jointAngle[0]);
	  printf("S2, U ARM = %ld (x100 deg)\r\n", rcvData->dataSrvPos.jointAngle[1]);
	  printf("S3, RotG = %ld (x100 deg)\r\n", rcvData->dataSrvPos.jointAngle[2]);
	  printf("S4, Grip = %ld (x100 deg)\r\n", rcvData->dataSrvPos.jointAngle[3]);
	  printf("S7, Pan = %ld (x100 deg)\r\n", rcvData->dataSrvPos.jointAngle[6]);
	  printf("S8, Tilt = %ld (x100 deg)\r\n", rcvData->dataSrvPos.jointAngle[7]);
	  sprintf(str, "Cmd Hex: %x %x %x %x %x %x ", g_CmdHandle.uCmd[0], g_CmdHandle.uCmd[1],
	  g_CmdHandle.uCmd[2], g_CmdHandle.uCmd[3], g_CmdHandle.uCmd[4], g_CmdHandle.uCmd[5] );

	  sprintf(str, "Srv PWM: %d %d %d %d %d %d ", rcvData->dataSrvPwm.currentPwm[0],
	  rcvData->dataSrvPwm.currentPwm[1],
	  rcvData->dataSrvPwm.currentPwm[2],
	  rcvData->dataSrvPwm.currentPwm[3],
	  // rcvData->dataSrvPwm.currentPwm[4],
	  // rcvData->dataSrvPwm.currentPwm[5],
	  rcvData->dataSrvPwm.currentPwm[6],
	  rcvData->dataSrvPwm.currentPwm[7] );
	  printf("%s \r\n", str);
	  sprintf(str, "Mtr PWM: %4.1f %4.1f ", rcvData->dataMtrPwm.dDutyCycPercentAL,
	  rcvData->dataMtrPwm.dDutyCycPercentBR );
	  printf("%s \r\n", str);
	  sprintf(str, "Rotation Vector: r:%0.6f i:%0.6f j:%0.6f k:%0.6f", // a:%0.6f deg t:%f",
	  rcvData->dataBNO085.real,
	  rcvData->dataBNO085.i,
	  rcvData->dataBNO085.j,
	  rcvData->dataBNO085.k
	  // rcvData->dataBNO085.accuracy,
	  // (float)(rcvData->dataBNO085.timestamp_uS /1000000.0)
	  );
	  printf("%s \r\n\r\n", str);

    osDelay( DEBUG_PRINT_DELAY);
  }
  /* USER CODE END StartDebugPrintTask */
}

void StartAdcTask(void *argument)
{
  /* USER CODE BEGIN StartAdcTask */
	// Task 2
	// ADC Task
	/* Wait for DISTANCE_SEN_READY ready */
	osEventFlagsWait( eventSysFlagsHandle, EVT_SYS_FLAG_DIS_READY, osFlagsNoClear, osWaitForever );
	// start ADC to measure voltages of MCU temp
	HAL_ADC_Start_IT(&hadc2);
	osDelay( 20 );
	/* ADC Task is ready */
	printf("\r\nADC initialized.\r\n");
	osEventFlagsSet (eventSysFlagsHandle, EVT_SYS_FLAG_ADC_READY);
	/* Wait for all devices ready */
	osEventFlagsWait( eventSysFlagsHandle, ( EVT_SYS_FLAG_ALL_READY ),
	( osFlagsNoClear | osFlagsWaitAll ), osWaitForever );

  /* Infinite loop */
  for(;;)
  {
	  // HAL_GPIO_TogglePin(LD1_GREEN_OB_GPIO_Port, LD1_GREEN_OB_Pin);
	  // HAL_GPIO_TogglePin(LD1_GREEN_SHLD_GPIO_Port, LD1_GREEN_SHLD_Pin);
	  HAL_ADC_Start_IT(&hadc2);
	  osDelay( ADC_TASK_DELAY );

  }
  /* USER CODE END StartAdcTask */
}

void StartCurSenTask(void *argument)
{
  /* USER CODE BEGIN StartCurSenTask */
	// Task 3
	// Current Sensing Task
	ROBOT * rcvData = (ROBOT *) argument;
	/* Wait for ADC ready */
	osEventFlagsWait( eventSysFlagsHandle, EVT_SYS_FLAG_ADC_READY,
	osFlagsNoClear, osWaitForever );
	INA219_Init();
	osDelay( 20 );
	printf("\r\nINA219 initialized.\r\n");
	osEventFlagsSet (eventSysFlagsHandle, EVT_SYS_FLAG_CUR_READY);
	/* Wait for all devices ready */
	osEventFlagsWait( eventSysFlagsHandle, ( EVT_SYS_FLAG_ALL_READY ),
	( osFlagsNoClear | osFlagsWaitAll ), osWaitForever );

  /* Infinite loop */
  for(;;)
  {
	  rcvData->dataINA219.shunt_voltage = INA219_shunt_voltage();
	  rcvData->dataINA219.bus_voltage = INA219_bus_voltage();
	  rcvData->dataINA219.current = INA219_current();
	  rcvData->dataINA219.power = INA219_power();
	  osDelay( CURRENT_SENSE_DELAY );

  }
  /* USER CODE END StartCurSenTask */
}

void StartDistSenTask(void *argument)
{
  /* USER CODE BEGIN StartDistSenTask */
	// Task 4
	// Distance Sensing Task
	ROBOT * rcvData = (ROBOT *) argument;
	/* VL53L0X */
	int nDevPresent = 0;
	int nDev = 3; // no. of VL53L0X devices
	char strBuf[64] = {0};
	/* Wait for GUI ready */
	osEventFlagsWait( eventSysFlagsHandle, EVT_SYS_FLAG_GUI_READY,
	osFlagsNoClear, osWaitForever );
	// VL53L0X: LONG_RANGE, HIGH_SPEED, HIGH_ACCURACY
	RangingConfig_e rangingConfig = HIGH_ACCURACY;
	// initialize all VL53L0X sensors
	printf("\r\nInitialize VL53L0X . . .\r\n");
	// get the number of detected devices
	nDevPresent = VL53L0X_DetectSensors(nDev);
	printf("\r\nVL53L0X: nDevPresent (detected) = %d, nDev (specified) = %d \r\n", nDevPresent,
	nDev);
	osDelay(10);
	// Setup all detected sensors for single shot mode and setup ranging configuration
	VL53L0X_SetupSingleShot(rangingConfig, nDev);
	osDelay(10);
	// start distance sensing measurement
	VL53L0X_StartMeasurementWaitExtInt(rangingConfig, nDev);
	// osDelay( DISTANCE_SENSE_DELAY );
	osDelay(20);
	/* distance sensing task is ready */
	printf("\r\nVL53L0X initialized.\r\n");
	osEventFlagsSet (eventSysFlagsHandle, EVT_SYS_FLAG_DIS_READY);
	/* Wait for all devices ready */
	osEventFlagsWait( eventSysFlagsHandle, ( EVT_SYS_FLAG_ALL_READY ),
	( osFlagsNoClear | osFlagsWaitAll ), osWaitForever );

  /* Infinite loop */
  for(;;)
  {
	  HAL_GPIO_TogglePin(LD2_YELLOW_OB_GPIO_Port, LD2_YELLOW_OB_Pin);
	  // HAL_GPIO_TogglePin(LD1_GREEN_OB_GPIO_Port, LD1_GREEN_OB_Pin);
	  // send to PC the first measured distance
	  sprintf(strBuf,"@D%4d#", rcvData->dataVL53L0X.RangeMilliMeter[0]);
	  CommandSendToHost( &g_CmdHandle, strBuf, strlen(strBuf));
	  // start distance sensing measurement
	  VL53L0X_StartMeasurementWaitExtInt(rangingConfig, nDev);
	  osDelay( 100 );
  }
  /* USER CODE END StartDistSenTask */
}

void StartSdCardTask(void *argument)
{
  /* USER CODE BEGIN StartSdCardTask */
	// Task 5
	 // SD Card Data Storing Task
	 ROBOT * rcvData = (ROBOT *) argument;
	 float temperature;
	 float current;
	 int power;
	 /* Wait for CUR ready */
	 osEventFlagsWait( eventSysFlagsHandle, EVT_SYS_FLAG_CUR_READY,
	 osFlagsNoClear, osWaitForever );
	 /* SD Card initialization */
	 printf("\r\nInitialize SD Card . . .\r\n");
	 sd_mount();
	 sd_get_free();
	 sd_open_file();
	 // sd_de_mount();
	 osDelay( 20 );
	 printf("\r\nSD Card initialized.\r\n");
	 osEventFlagsSet (eventSysFlagsHandle, EVT_SYS_FLAG_SDC_READY);
	 /* Wait for all devices ready */
	 osEventFlagsWait( eventSysFlagsHandle, ( EVT_SYS_FLAG_ALL_READY ),
	 ( osFlagsNoClear | osFlagsWaitAll ), osWaitForever );
	 /* Infinite loop */
	 for(;;)
	 {
	  HAL_GPIO_TogglePin(LD1_GREEN_OB_GPIO_Port, LD1_GREEN_OB_Pin);
	  temperature = 100.0 * ((float)rcvData->mcuTempU32 - (float)(*TS_CAL1)) /
	    (float)((*TS_CAL2 - *TS_CAL1)) + 30.0;
	  current = (float)(rcvData->dataINA219.current) / 10.0;
	  power = rcvData->dataINA219.power;
	  sd_write_file(temperature,current,power); //write mcu temp, current, power
	  osDelay( SD_CARD_TASK_DELAY );
	 }
  /* USER CODE END StartSdCardTask */
}

void StartMtrEncoderTask(void *argument)
{
  /* USER CODE BEGIN StartMtrEncoderTask */
	// Task 6
	// Motor Encoder Reading Task
	ROBOT * rcvData = (ROBOT *) argument;
	int i = 0;
	uint32_t wakeuptime;
	wakeuptime = osKernelSysTick();
  /* Infinite loop */
  for(;;)
  {
	  for (i = 4; i > 0; i--)
	  {
		  // update previous counts and velocities
		  rcvData->dataEncoder.mtrCnt16AL[i] = rcvData->dataEncoder.mtrCnt16AL[i-1]; // motor 1
		  rcvData->dataEncoder.mtrCnt16BR[i] = rcvData->dataEncoder.mtrCnt16BR[i-1]; // motor 2
		  rcvData->dataEncoder.mtrVel32AL[i] = rcvData->dataEncoder.mtrVel32AL[i-1]; // motor 1
		  rcvData->dataEncoder.mtrVel32BR[i] = rcvData->dataEncoder.mtrVel32BR[i-1]; // motor 2
	  }
	  // obtain motor encoder counts
		  rcvData->dataEncoder.mtrCnt16AL[0] = (int16_t)(E1_TIM_BASE->CNT)*(-1); // motor 1
		  rcvData->dataEncoder.mtrCnt16BR[0] = (int16_t)(E2_TIM_BASE->CNT); // motor 2
	  // obtain motor velocities

      rcvData->dataEncoder.mtrVel32AL[0] = (int32_t)((int16_t)(rcvData->dataEncoder.mtrCnt16AL[0] - rcvData->dataEncoder.mtrCnt16AL[1]));
	  rcvData->dataEncoder.mtrVel32BR[0] = (int32_t)((int16_t)(rcvData->dataEncoder.mtrCnt16BR[0] - rcvData->dataEncoder.mtrCnt16BR[1]));

	  wakeuptime += (uint32_t)MTR_SAMPLING_TIME;
	  osDelayUntil( wakeuptime );
  }
  /* USER CODE END StartMtrEncoderTask */
}

void StartSrvPwmUpdateTask(void *argument)
{
  /* USER CODE BEGIN StartSrvPwmUpdateTask */
	// Task 7
	// Servo PWM Update Task
	ROBOT * rcvData = (ROBOT *) argument;
	int i = 0;
	int diff = 0;
	char strBuf[64] = {0};
	/* Wait for all devices ready */
	osEventFlagsWait( eventSysFlagsHandle, ( EVT_SYS_FLAG_ALL_READY ),
	( osFlagsNoClear | osFlagsWaitAll ), osWaitForever );

  /* Infinite loop */
  for(;;)
  {
	  // We have 8 servos to move. This is a method to move servo gradually by certain steps
	  for( i=0; i<8; i++ )
	  {
		  // Check if current PWM is matched with desired PWM.
		  if( g_CmdHandle.TargetPwm[i].Value == rcvData->dataSrvPwm.currentPwm[i])
		  {
			  // ensure servo motor is updated with the current PWM duty-cycle
			  ServoSetDuty( (i+1), rcvData->dataSrvPwm.currentPwm[i] );
			  // If PC application needs to know PWM movement is done
			  if( 0 != g_CmdHandle.TargetPwm[i].bReqCompleted )
			  {
				  g_CmdHandle.TargetPwm[i].bReqCompleted = 0; // request completed
				  // Send to wifi router via UART then it will route to PC app over TCP
				  strBuf[0] = '@';
				  strBuf[1] = 'C';
				  strBuf[2] = '0';
				  strBuf[3] = (i+1) + 0x30;// Convert to ascii
				  strBuf[4] = '#';
				  strBuf[5] = 0;
				  CommandSendToHost( &g_CmdHandle, strBuf, strlen(strBuf) );
			  }
			  // go to next servo
			  continue;
		  }
		  // If current PWM is not same as desired PWM, we need to step it
		  // Calculate the difference
		  diff = g_CmdHandle.TargetPwm[i].Value - rcvData->dataSrvPwm.currentPwm[i];
		  // If difference is too small, smaller a step value, just set it to desired value
		  if( abs(diff) <= g_CmdHandle.nDutyStep ) // <= 1% g_CmdHandle.nDutyStep
		  {
			  rcvData->dataSrvPwm.currentPwm[i] = g_CmdHandle.TargetPwm[i].Value;
		  }
		  else
		  {
			  // Otherwise, we step servo base on direction
			  if( diff < 0 )
			  {
				  rcvData->dataSrvPwm.currentPwm[i] -= g_CmdHandle.nDutyStep;
			  }
			  else
			  {
				  rcvData->dataSrvPwm.currentPwm[i] += g_CmdHandle.nDutyStep;
			  }
		  }
		  // Set physically the PWNM duty cycle for servo
		  switch( i+1 ) // Servo start from 1
		  {
			  case CMD_SV1_TARGET_ANGLE:
			  ServoSetDuty( 1, rcvData->dataSrvPwm.currentPwm[i] );
			  break;
			  case CMD_SV2_TARGET_ANGLE:
			  ServoSetDuty( 2, rcvData->dataSrvPwm.currentPwm[i] );
			  break;
			  case CMD_SV3_TARGET_ANGLE:
			  ServoSetDuty( 3, rcvData->dataSrvPwm.currentPwm[i] );
			  break;
			  case CMD_SV4_TARGET_ANGLE:
			  ServoSetDuty( 4, rcvData->dataSrvPwm.currentPwm[i] );
			  break;
			  case CMD_SV5_TARGET_ANGLE:
			  ServoSetDuty( 5, rcvData->dataSrvPwm.currentPwm[i] );
			  break;
			  case CMD_SV6_TARGET_ANGLE:
			  ServoSetDuty( 6, rcvData->dataSrvPwm.currentPwm[i] );
			  break;
			  case CMD_SV7_TARGET_ANGLE:
			  ServoSetDuty( 7, rcvData->dataSrvPwm.currentPwm[i] );
			  break;
			  case CMD_SV8_TARGET_ANGLE:
			  ServoSetDuty( 8, rcvData->dataSrvPwm.currentPwm[i] );
			  break;
			  default:
			  break;
		  }
	  }
	  osDelay( SRV_PWM_UPDATE_TIME );
  }
  /* USER CODE END StartSrvPwmUpdateTask */
}

void StartCmdRxTask(void *argument)
{
  /* USER CODE BEGIN StartCmdRxTask */
	// Task 8
	// Command Receive Task
	// ROBOT * rcvData = (ROBOT *) argument;
	/* WiFi Serial to net command initialization */
	// put in main.c
	// CommandInit( &g_CmdHandle, &huart2 );
	/* Wait for all devices ready */
	osEventFlagsWait( eventSysFlagsHandle, ( EVT_SYS_FLAG_ALL_READY ),
	( osFlagsNoClear | osFlagsWaitAll ), osWaitForever );
  /* Infinite loop */
  for(;;)
  {
	  CommandRxExe( &g_CmdHandle );
	  // osDelay( COMMAND_RX_DELAY );

  }
  /* USER CODE END StartCmdRxTask */
}

void StartGuiLcdDispTask(void *argument)
{
  /* USER CODE BEGIN StartGuiLcdDispTask */
	// Task 9
	// GUI LCD Display Task
	ROBOT * rcvData = (ROBOT *) argument;
	char str[128] = {0};
	float temperature = 0.0;
	int i = 0;
	/* LCD initialization */
	_LcdInit();
	GUI_SetFont(&GUI_Font6x8);
	/* LCD is ready */
	printf("\r\nLCD initialized.\r\n");
	osEventFlagsSet (eventSysFlagsHandle, EVT_SYS_FLAG_GUI_READY);
	/* Wait for all devices ready */
	osEventFlagsWait( eventSysFlagsHandle, ( EVT_SYS_FLAG_ALL_READY ),
	( osFlagsNoClear | osFlagsWaitAll ), osWaitForever );

  /* Infinite loop */
  for(;;)
  {
	  HAL_GPIO_TogglePin(LD3_RED_OB_GPIO_Port, LD3_RED_OB_Pin);
	  sprintf(str, "Cmd Hex: %x %x %x %x %x %x ",
	  g_CmdHandle.uCmd[0],
	  g_CmdHandle.uCmd[1],
	  g_CmdHandle.uCmd[2],
	  g_CmdHandle.uCmd[3],
	  g_CmdHandle.uCmd[4],
	  g_CmdHandle.uCmd[5] );
	  GUI_SetBkColor(GUI_BLUE);
	  GUI_DispStringAt( str, 2, 60 );
	  sprintf(str, "Srv PWM: %d %d %d %d %d %d ",
		  rcvData->dataSrvPwm.currentPwm[0],
		  rcvData->dataSrvPwm.currentPwm[1],
		  rcvData->dataSrvPwm.currentPwm[2],
		  rcvData->dataSrvPwm.currentPwm[3],
		  // rcvData->dataSrvPwm.currentPwm[4],
		  // rcvData->dataSrvPwm.currentPwm[5],
		  rcvData->dataSrvPwm.currentPwm[6],
		  rcvData->dataSrvPwm.currentPwm[7] );
	  GUI_SetBkColor(GUI_BLUE);
	  GUI_DispStringAt( str, 2, 75 );

	  sprintf(str, "Mtr Enc: %5d %5d ", rcvData->dataEncoder.mtrCnt16AL[0],
			  rcvData->dataEncoder.mtrCnt16BR[0] );
	  GUI_SetBkColor(GUI_BLUE);
	  GUI_DispStringAt( str, 2, 90 );

	  /*************************************************************************/
	  sprintf(str, "Cur: %4.1ld ", rcvData->dataINA219.current);
	  GUI_SetBkColor(GUI_BLUE);
	  GUI_DispStringAt( str, 2, 105 );

	  sprintf(str, "Pwr: %4.1ld", rcvData->dataINA219.power);
	  GUI_SetBkColor(GUI_BLUE);
	  GUI_DispStringAt( str, 2, 120 );
	  /*************************************************************************/
	  temperature = 100.0 * ((float)rcvData->mcuTempU32 - (float)(*TS_CAL1)) /
		  (float)((*TS_CAL2 - *TS_CAL1)) + 30.0;

	  sprintf(str, "MCU Temp: %6.2f (degC)\r\n", temperature);
	  GUI_SetBkColor(GUI_BLUE);
	  GUI_DispStringAt(str, 2, 150 );
	  sprintf(str, "%2d", i);
	  i++;
	  if (i >= 100) i = 0;
	  GUI_SetBkColor(GUI_BLUE);
	  GUI_DispStringAt( str, 2, 165 );
	  osDelay( 300 );
  }
  /* USER CODE END StartGuiLcdDispTask */
}

void StartImuTask(void *argument)
{
  /* USER CODE BEGIN StartImuTask */
	// Task 10
	// IMU Task Task
	// ROBOT * rcvData = (ROBOT *) argument;
	/* Wait for SD Card ready */
	osEventFlagsWait( eventSysFlagsHandle, EVT_SYS_FLAG_SDC_READY,
	osFlagsNoClear, osWaitForever );
	// Initialize the BNO085
	printf("\r\nInitialize BNO085 . . .\r\n");
	HAL_TIM_Base_Start(&htim5);
	BNO085_init();
	osDelay( 20 );
	printf("\r\nBNO085 initialized.\r\n");
	osEventFlagsSet (eventSysFlagsHandle, EVT_SYS_FLAG_IMU_READY);
	osEventFlagsSet (eventSysFlagsHandle, EVT_SYS_FLAG_ALL_READY);
	/* Wait for all devices ready */
	osEventFlagsWait( eventSysFlagsHandle, ( EVT_SYS_FLAG_ALL_READY ),
	( osFlagsNoClear | osFlagsWaitAll ), osWaitForever );

  /* Infinite loop */
  for(;;)
  {
	  // HAL_GPIO_TogglePin(LD3_RED_OB_GPIO_Port, LD3_RED_OB_Pin);
	  BNO085_service();
	  osDelay( IMU_TASK_DELAY ); // 25 Hz, timing is set in BNO085_spi.c

  }
  /* USER CODE END StartImuTask */
}

/* USER CODE BEGIN Application */
static void _LcdInit( void )
{
	// Choosing a landscape orientation
	LcdInit( &hspi2, LCD_LANDSCAPE_180 );
	GUI_Init();
	GUI_SetBkColor(GUI_BLUE);
	GUI_Clear();
	GUI_SetFont(&GUI_Font8x18);
	GUI_SetTextMode(GUI_TM_NORMAL);
	GUI_SetColor(GUI_BLACK);
	GUI_DispStringHCenterAt("Welcome to ECE225/SEM4405", 110, 10 );
	GUI_DispStringHCenterAt("Robotics", 110, 25 );
	GUI_DispStringHCenterAt("by Gan LC & Liaw HC, 2024", 110, 40 );
}
void HAL_ADC_ConvCpltCallback(ADC_HandleTypeDef* hadc)
{
	if( hadc->Instance == ADC2 ) robot.mcuTempU32 = HAL_ADC_GetValue(&hadc2);
}
void HAL_GPIO_EXTI_Callback(uint16_t GPIO_Pin)
{
		if( GPIO_Pin == GPIO_PIN_13 )
		{
			HAL_GPIO_TogglePin(LD3_RED_OB_GPIO_Port, LD3_RED_OB_Pin);
		}
	if( GPIO_Pin == IMU_INT_IRQ_Pin ) // IMU
	{
		IMU_Activate();
	}
	// Interrupt handler called each time an interrupt is produced by the ranging sensor
	#if (VL53L0X_ALARM_INTERRUPT_MODE || VL53L0X_START_MEASUREMENT_WAIT_EXT_INT)
	if(GPIO_Pin == GPIO_PIN_2) // DIST1_IRQ EXTI2_Pin
	{
		// first device
		VL53L0X_InterruptHandler(1);
		robot.dataVL53L0X.TimeStamp[0] = RangingMeasurementData[0].TimeStamp;
		robot.dataVL53L0X.RangeStatus[0] = RangingMeasurementData[0].RangeStatus;
		robot.dataVL53L0X.RangeMilliMeter[0] = RangingMeasurementData[0].RangeMilliMeter;
		robot.dataVL53L0X.SignalRateRtnMegaCps[0] = RangingMeasurementData[0].SignalRateRtnMegaCps;
		robot.dataVL53L0X.AmbientRateRtnMegaCps[0] = RangingMeasurementData[0].AmbientRateRtnMegaCps;
		robot.dataVL53L0X.EffectiveSpadRtnCount[0] = RangingMeasurementData[0].EffectiveSpadRtnCount;
		robot.dataVL53L0X.RangeDMaxMilliMeter[0] = RangingMeasurementData[0].RangeDMaxMilliMeter;
	}

	if(GPIO_Pin == GPIO_PIN_3) // DIST2_IRQ EXTI3_Pin
	{
		// second device
		VL53L0X_InterruptHandler(2);
		robot.dataVL53L0X.TimeStamp[1] = RangingMeasurementData[1].TimeStamp;
		robot.dataVL53L0X.RangeStatus[1] = RangingMeasurementData[1].RangeStatus;
		robot.dataVL53L0X.RangeMilliMeter[1] = RangingMeasurementData[1].RangeMilliMeter;
		robot.dataVL53L0X.SignalRateRtnMegaCps[1] = RangingMeasurementData[1].SignalRateRtnMegaCps;
		robot.dataVL53L0X.AmbientRateRtnMegaCps[1] = RangingMeasurementData[1].AmbientRateRtnMegaCps;
		robot.dataVL53L0X.EffectiveSpadRtnCount[1] = RangingMeasurementData[1].EffectiveSpadRtnCount;
		robot.dataVL53L0X.RangeDMaxMilliMeter[1] = RangingMeasurementData[1].RangeDMaxMilliMeter;
	}
	if(GPIO_Pin == GPIO_PIN_4) // DIST3_IRQ EXTI4_Pin
	{
		// third device
		VL53L0X_InterruptHandler(3);
		robot.dataVL53L0X.TimeStamp[2] = RangingMeasurementData[2].TimeStamp;
		robot.dataVL53L0X.RangeStatus[2] = RangingMeasurementData[2].RangeStatus;
		robot.dataVL53L0X.RangeMilliMeter[2] = RangingMeasurementData[2].RangeMilliMeter;
		robot.dataVL53L0X.SignalRateRtnMegaCps[2] = RangingMeasurementData[2].SignalRateRtnMegaCps;
		robot.dataVL53L0X.AmbientRateRtnMegaCps[2] = RangingMeasurementData[2].AmbientRateRtnMegaCps;
		robot.dataVL53L0X.EffectiveSpadRtnCount[2] = RangingMeasurementData[2].EffectiveSpadRtnCount;
		robot.dataVL53L0X.RangeDMaxMilliMeter[2] = RangingMeasurementData[2].RangeDMaxMilliMeter;
	}
	#endif
}
int __io_putchar(int ch)
{
uint8_t c[1];
c[0] = ch & 0x00FF; // &c[0]
HAL_UART_Transmit(&huart3, &*c, 1, 10);
return ch;
}

	/*
	int _write(int file, char *ptr, int len)
	{
		int DataIdx;
		for(DataIdx= 0; DataIdx< len; DataIdx++)
		{
			__io_putchar(*ptr++);
		}
		return len;
	}*/

/* USER CODE END Application */
